# SPC1169 register map
File version: 2022071043481212
CPU: cm4 r1p0, little endian, no MPU, FPU, 4 interrupt priority bits
Registers are 32-bit, read-write, reset 0x0 unless marked. A register's access mark holds for its fields unless they carry their own. Offsets are from the block's base; [hi:lo] are bit positions; {n}, {i} and the like mark numbered series; 'fields as' and 'values as' point back to an identical list.

## PHCOMP
Base 0x40000500
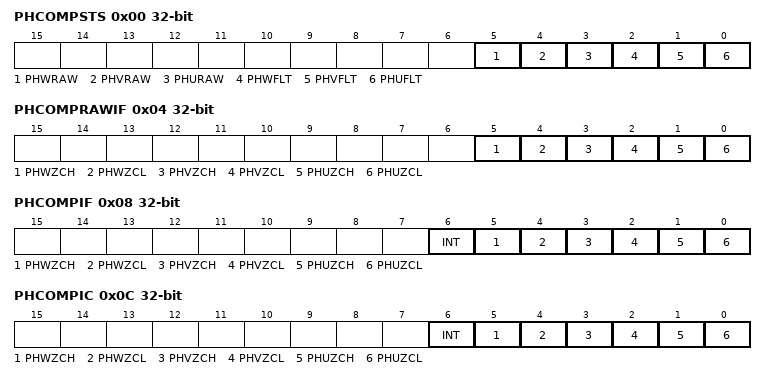
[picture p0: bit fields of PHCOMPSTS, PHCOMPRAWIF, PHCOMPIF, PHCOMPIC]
0x00 PHCOMPSTS ro — Phase Comparison Status Register
  [all] fields
    0=LOW; 1=HIGH
  [5] PHWRAW — W-phase realtime original output status
  [4] PHVRAW — V-phase realtime original output status
  [3] PHURAW — U-phase realtime original output status
  [2] PHWFLT — W-phase realtime filtered output status
  [1] PHVFLT — V-phase realtime filtered output status
  [0] PHUFLT — U-phase realtime filtered output status
0x04 PHCOMPRAWIF ro — Phase Comparison Raw Interrupt Flag Register
  [all] fields
    0=NOT_OCCUR (Event does not occur); 1=OCCUR (Event occurred)
  [5] PHWZCH — W-phase zero-cross to high event flag
  [4] PHWZCL — W-phase zero-cross to low event flag
  [3] PHVZCH — V-phase zero-cross to high event flag
  [2] PHVZCL — V-phase zero-cross to low event flag
  [1] PHUZCH — U-Phase zero-cross to high event flag
  [0] PHUZCL — U-Phase zero-cross to low event flag
0x08 PHCOMPIF ro — Phase Comparison Interrupt Flag Register
  [6] INT — Global phase comparison interrupt flag
    0=NOT_OCCUR (Interrupt does not occur); 1=OCCUR (Interrupt occurred and issued to the CPU. Further interrupt will not be generated until this bit is cleared)
  [5] PHWZCH — W-phase zero-cross to high interrupt flag
    0=NOT_OCCUR (Interrupt does not occur); 1=OCCUR (Interrupt occurred. Further event will not trigger interrupt until this bit is cleared)
  [4] PHWZCL — W-phase zero-cross to low interrupt flag
    values as PHWZCH
  [3] PHVZCH — V-phase zero-cross to high interrupt flag
    values as PHWZCH
  [2] PHVZCL — V-phase zero-cross to low interrupt flag
    values as PHWZCH
  [1] PHUZCH — V-phase zero-cross to high interrupt flag
    values as PHWZCH
  [0] PHUZCL — U-Phase zero-cross to low interrupt flag
    values as PHWZCH
0x0C PHCOMPIC — Phase Comparison Interrupt Clear Register
  [all] fields
    0=NO_EFFECT (Write a 0 has no effect. Always readback 0); 1=CLEAR (Write a 1 clears the flag. This bit is self-cleared.)
  [6] INT — Global phase comparison interrupt clear
  [5] PHWZCH — W-Phase zero-cross to high interrupt clear
  [4] PHWZCL — W-Phase zero-cross to low interrupt clear
  [3] PHVZCH — V-phase zero-cross to high interrupt clear
  [2] PHVZCL — V-phase zero-cross to low interrupt clear
  [1] PHUZCH — V-phase zero-cross to high interrupt clear
  [0] PHUZCL — U-Phase zero-cross to low interrupt clear
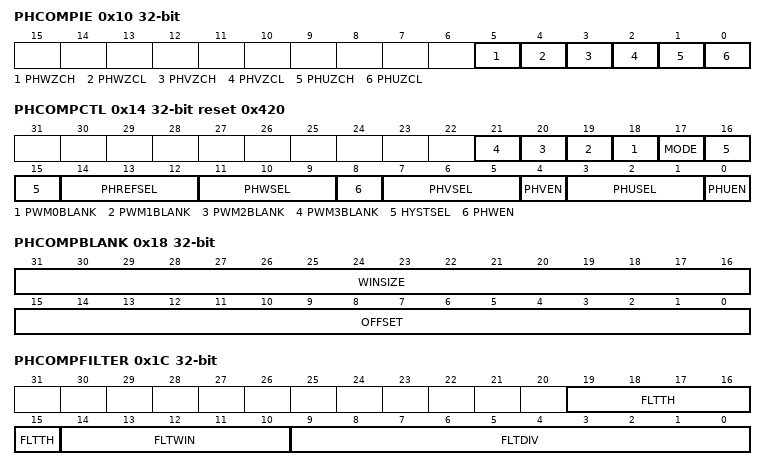
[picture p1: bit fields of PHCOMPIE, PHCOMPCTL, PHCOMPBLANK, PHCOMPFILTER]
0x10 PHCOMPIE — Phase Comparison Interrupt Enable Register
  [all] fields
    0=DISABLE; 1=ENABLE
  [5] PHWZCH — W-Phase zero-cross to high interrupt enable
  [4] PHWZCL — W-Phase zero-cross to low interrupt enable
  [3] PHVZCH — V-phase zero-cross to high interrupt enable
  [2] PHVZCL — V-phase zero-cross to low interrupt enable
  [1] PHUZCH — U-phase zero-cross to high interrupt enable
  [0] PHUZCL — U-Phase zero-cross to low interrupt enable
0x14 PHCOMPCTL reset 0x420 — Phaes Comparison Control Register
  [n+18] PWM{n}BLANK (n=0..3) — Trigger blanking due to PWM{n} toggling
    0=DISABLE; 1=ENABLE
  [17] MODE — Operation mode
    0=BEMF_PHCOMP (Phase comparator mode for back EMF sensing); 1=NORMAL_COMP (Normal voltage comparator)
  [16:15] HYSTSEL — Comparitor hysterisis select
    0=0_MV; 1=12_MV; 2=24_MV; 3=36_MV
  [14:12] PHREFSEL — Phase comparitor reference select
    0=PHC (Common-node sensed signal); 1=DAC1 (DAC1 output); 2=DAC2 (DAC2 output); {v}=ANA_IN{v-3} (ANA_IN{v-3} pin input) (v=3..7)
  [11:9] PHWSEL — W-Phase comparitor input channel select
    0=PHU (U-Phase sensed signal); 1=PHV (V-Phase sensed signal); 2=PHW (W-Phase sensed signal); {v}=ANA_IN{v-3} (ANA_IN{v-3} pin input) (v=3..7)
  [8] PHWEN — W-phase comparion enable
    0=DISABLE; 1=ENABLE
  [7:5] PHVSEL — V-Phase comparitor input channel select
    values as PHWSEL
  [4] PHVEN — V-phase comparitor enable
    0=DISABLE; 1=ENABLE
  [3:1] PHUSEL — U-Phase comparitor input channel select
    values as PHWSEL
  [0] PHUEN — U-phase comparitor enable
    0=DISABLE; 1=ENABLE
0x18 PHCOMPBLANK — Phase Comparison Blanking Control
  [31:16] WINSIZE — Blanking window size
  [15:0] OFFSET — Blanking window offset referred to the toggling of all PWM outputs
0x1C PHCOMPFILTER — Phase Comparison Filter Control
  [19:15] FLTTH — Set the filter's threhold to (FLTTH+1) 1's/0's for output to toggle
  [14:10] FLTWIN — Set the filter's window size to (FLTWIN+1) samples
  [9:0] FLTDIV — Set the filter's clock dividing ratio to (FLTDIV+1)
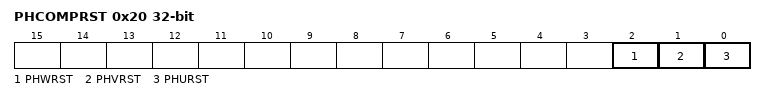
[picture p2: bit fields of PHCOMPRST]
0x20 PHCOMPRST — Phase Comparison FSM Reset Register
  [all] fields
    0=NO_EFFECT (Write 0 has no effect. Always reads back 0.); 1=RESET (Write 1 resets the FSM. This bit is self-cleared)
  [2] PHWRST — Reset W-phase comparison state machine. In BEMF phase comparitor mode, the 1st zero-cross event will be ignored after the reset pulse
  [1] PHVRST — Reset V-phase comparison state machine. In BEMF phase comparitor mode, the 1st zero-cross event will be ignored after the reset pulse
  [0] PHURST — Reset U-phase comparison state machine. In BEMF phase comparitor mode, the 1st zero-cross event will be ignored after the reset pulse
0x24 PHCOMPREGKEY reset 0x1ACCE551 — Phase Comparison Register Write-Allow Key Register
  [31:0] KEY — Write 0x1ACCE551 to unlock protected registers
